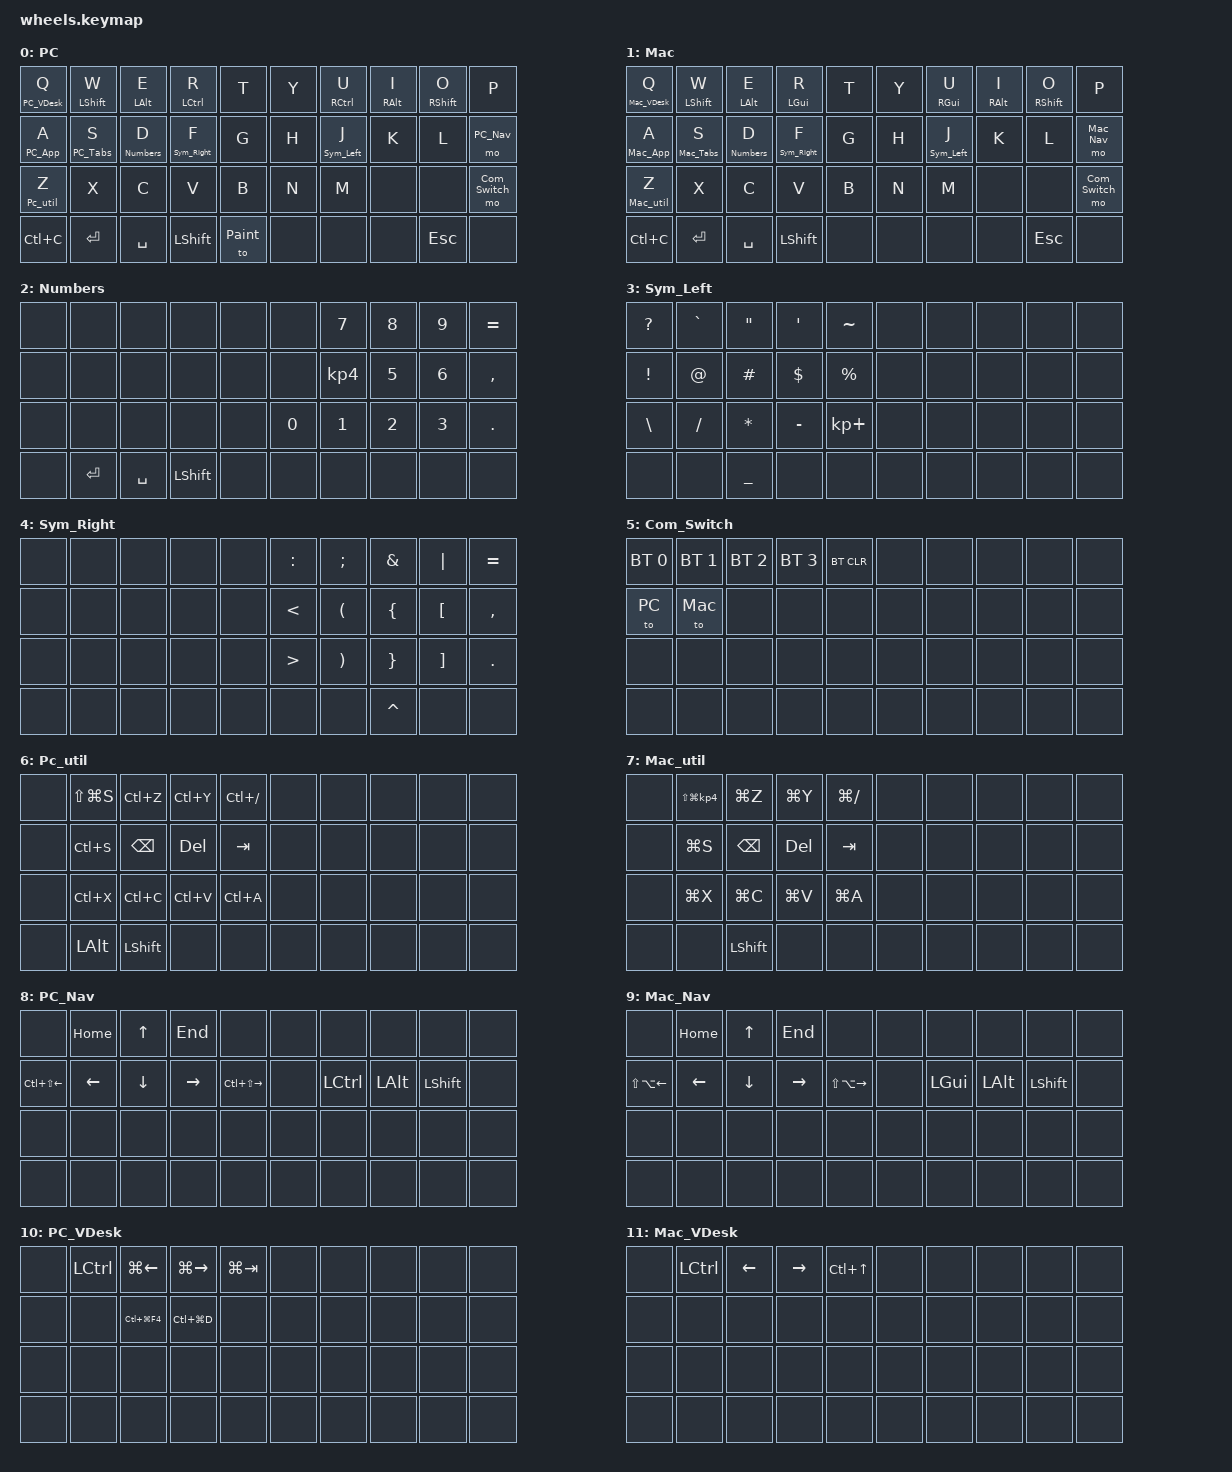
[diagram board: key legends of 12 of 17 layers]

/*
* Copyright (c) 2020 The ZMK Contributors 
* SPDX-License-Identifier: MIT 
*/ 

#include <behaviors.dtsi> 
#include <dt-bindings/zmk/keys.h> 
#include <dt-bindings/zmk/bt.h> 

#define PC 0 
#define Mac 1 
#define Numbers 2 
#define Sym_Left 3 
#define Sym_Right 4 
#define Com_Switch 5 
#define Pc_util 6 
#define Mac_util 7 
#define PC_Nav 8 
#define Mac_Nav 9 
#define PC_VDesk 10 
#define Mac_VDesk 11 
#define PC_App 12 
#define Mac_App 13 
#define PC_Tabs 14 
#define Mac_Tabs 15 
#define Paint 16 
    
/ {
    behaviors {
        hm: homerow_mods {
            compatible = "zmk,behavior-hold-tap";
            label = "HOMEROW_MODS";
            #binding-cells = <2>;
            tapping-term-ms = <300>;
            quick-tap-ms = <200>;
            flavor = "tap-preferred";
            bindings = <&kp>, <&kp>;
        };
    };
    keymap {
    compatible = "zmk,keymap";

    PC_layer {
            label = "PC";
            sensor-bindings = < 
              &inc_dec_kp   A   B // 1st: Targets left_horizonal_encoder
              &inc_dec_kp   PAGE_DOWN   PAGE_UP // 2nd: Targets left_vertical_encoder
              >;
            bindings = <
                          &lt PC_VDesk Q   &hm LSHIFT W     &hm LALT E       &hm LCTRL R      &kp T            &kp Y            &hm RCTRL U      &hm RALT I       &hm RSHIFT O     &kp P             
                          &lt PC_App A     &lt PC_Tabs S    &lt Numbers D    &lt Sym_Right F  &kp G            &kp H            &lt Sym_Left J   &kp K            &kp L            &mo PC_Nav        
                          &lt Pc_util Z    &kp X            &kp C            &kp V            &kp B            &kp N            &kp M            &none            &none            &mo Com_Switch    
                          &kp LC(C)        &kp ENTER        &kp SPACE        &kp LSHIFT       &to Paint        &none            &none            &none            &kp ESC          &none             
            >;
          };
            
Mac_layer {
            label = "Mac";
            sensor-bindings = < 
              &inc_dec_kp  0  0 // 1st: Targets left_horizonal_encoder
              &inc_dec_kp  0  0 // 2nd: Targets left_vertical_encoder
              >;
            bindings = <
                          &lt Mac_VDesk Q  &hm LSHIFT W     &hm LALT E       &hm LGUI R       &kp T            &kp Y            &hm RGUI U       &hm RALT I       &hm RSHIFT O     &kp P             
                          &lt Mac_App A    &lt Mac_Tabs S   &lt Numbers D    &lt Sym_Right F  &kp G            &kp H            &lt Sym_Left J   &kp K            &kp L            &mo Mac_Nav       
                          &lt Mac_util Z   &kp X            &kp C            &kp V            &kp B            &kp N            &kp M            &none            &none            &mo Com_Switch    
                          &kp LC(C)        &kp ENTER        &kp SPACE        &kp LSHIFT       &none            &none            &none            &none            &kp ESC          &none             
            >;
          };
            
Numbers_layer {
            label = "Numbers";
            sensor-bindings = < 
              &inc_dec_kp  0  0 // 1st: Targets left_horizonal_encoder
              &inc_dec_kp  0  0 // 2nd: Targets left_vertical_encoder
              >;
            bindings = <
                          &none            &none            &none            &none            &none            &none            &kp N7           &kp N8           &kp N9           &kp EQUAL         
                          &none            &none            &none            &none            &none            &none            &kp KP_N4        &kp N5           &kp N6           &kp COMMA         
                          &none            &none            &none            &none            &none            &kp N0           &kp N1           &kp N2           &kp N3           &kp DOT           
                          &none            &kp ENTER        &kp SPACE        &kp LSHIFT       &none            &none            &none            &none            &none            &none             
            >;
          };
            
Sym_Left_layer {
            label = "Sym_Left";
            sensor-bindings = < 
              &inc_dec_kp  0  0 // 1st: Targets left_horizonal_encoder
              &inc_dec_kp  0  0 // 2nd: Targets left_vertical_encoder
              >;
            bindings = <
                          &kp QMARK        &kp GRAVE        &kp DQT          &kp SINGLE_QUOTE &kp TILDE        &none            &none            &none            &none            &none             
                          &kp EXCL         &kp AT           &kp HASH         &kp DOLLAR       &kp PERCENT      &none            &none            &none            &none            &none             
                          &kp BACKSLASH    &kp SLASH        &kp ASTRK        &kp MINUS        &kp KP_PLUS      &none            &none            &none            &none            &none             
                          &none            &none            &kp UNDERSCORE   &none            &none            &none            &none            &none            &none            &none             
            >;
          };
            
Sym_Right_layer {
            label = "Sym_Right";
            sensor-bindings = < 
              &inc_dec_kp  0  0 // 1st: Targets left_horizonal_encoder
              &inc_dec_kp  0  0 // 2nd: Targets left_vertical_encoder
              >;
            bindings = <
                          &none            &none            &none            &none            &none            &kp COLON        &kp SEMICOLON    &kp AMPERSAND    &kp PIPE         &kp EQUAL         
                          &none            &none            &none            &none            &none            &kp LESS_THAN    &kp LPAR         &kp LBRC         &kp LBKT         &kp COMMA         
                          &none            &none            &none            &none            &none            &kp GREATER_THAN &kp RPAR         &kp RBRC         &kp  RBKT        &kp DOT           
                          &none            &none            &none            &none            &none            &none            &none            &kp CARET        &none            &none             
            >;
          };
            
Com_Switch_layer {
            label = "Com_Switch";
            sensor-bindings = < 
              &inc_dec_kp  0  0 // 1st: Targets left_horizonal_encoder
              &inc_dec_kp  0  0 // 2nd: Targets left_vertical_encoder
              >;
            bindings = <
                          &bt BT_SEL 0     &bt BT_SEL 1     &bt BT_SEL 2     &bt BT_SEL 3     &bt BT_CLR       &none            &none            &none            &none            &none             
                          &to PC           &to Mac          &none            &none            &none            &none            &none            &none            &none            &none             
                          &none            &none            &none            &none            &none            &none            &none            &none            &none            &none             
                          &none            &none            &none            &none            &none            &none            &none            &none            &none            &none             
            >;
          };
            
Pc_util_layer {
            label = "Pc_util";
            sensor-bindings = < 
              &inc_dec_kp  0  0 // 1st: Targets left_horizonal_encoder
              &inc_dec_kp  0  0 // 2nd: Targets left_vertical_encoder
              >;
            bindings = <
                          &none            &kp LS(LG(S))    &kp LC(Z)        &kp LC(Y)        &kp LC(SLASH)    &none            &none            &none            &none            &none             
                          &none            &kp LC(S)        &kp BACKSPACE    &kp DEL          &kp TAB          &none            &none            &none            &none            &none             
                          &none            &kp LC(X)        &kp LC(C)        &kp LC(V)        &kp LC(A)        &none            &none            &none            &none            &none             
                          &none            &kp LALT         &kp LSHIFT       &none            &none            &none            &none            &none            &none            &none             
            >;
          };
            
Mac_util_layer {
            label = "Mac_util";
            sensor-bindings = < 
              &inc_dec_kp  0  0 // 1st: Targets left_horizonal_encoder
              &inc_dec_kp  0  0 // 2nd: Targets left_vertical_encoder
              >;
            bindings = <
                          &none            &kp LS(LG(KP_N4)) &kp LG(Z)        &kp LG(Y)        &kp LG(SLASH)    &none            &none            &none            &none            &none             
                          &none            &kp LG(S)        &kp BACKSPACE    &kp DEL          &kp TAB          &none            &none            &none            &none            &none             
                          &none            &kp LG(X)        &kp LG(C)        &kp LG(V)        &kp LG(A)        &none            &none            &none            &none            &none             
                          &none            &none            &kp LSHIFT       &none            &none            &none            &none            &none            &none            &none             
            >;
          };
            
PC_Nav_layer {
            label = "PC_Nav";
            sensor-bindings = < 
              &inc_dec_kp  0  0 // 1st: Targets left_horizonal_encoder
              &inc_dec_kp  0  0 // 2nd: Targets left_vertical_encoder
              >;
            bindings = <
                          &none            &kp HOME         &kp UP           &kp END          &none            &none            &none            &none            &none            &none             
                          &kp LC(LS(LEFT)) &kp LEFT         &kp DOWN         &kp RIGHT        &kp LC(LS(RIGHT)) &none            &kp LCTRL        &kp LALT         &kp LSHIFT       &none             
                          &none            &none            &none            &none            &none            &none            &none            &none            &none            &none             
                          &none            &none            &none            &none            &none            &none            &none            &none            &none            &none             
            >;
          };
            
Mac_Nav_layer {
            label = "Mac_Nav";
            sensor-bindings = < 
              &inc_dec_kp  0  0 // 1st: Targets left_horizonal_encoder
              &inc_dec_kp  0  0 // 2nd: Targets left_vertical_encoder
              >;
            bindings = <
                          &none            &kp HOME         &kp UP           &kp END          &none            &none            &none            &none            &none            &none             
                          &kp LS(LA(LEFT)) &kp LEFT         &kp DOWN         &kp RIGHT        &kp LS(LA(RIGHT)) &none            &kp LGUI         &kp LALT         &kp LSHIFT       &none             
                          &none            &none            &none            &none            &none            &none            &none            &none            &none            &none             
                          &none            &none            &none            &none            &none            &none            &none            &none            &none            &none             
            >;
          };
            
PC_VDesk_layer {
            label = "PC_VDesk";
            sensor-bindings = < 
              &inc_dec_kp  0  0 // 1st: Targets left_horizonal_encoder
              &inc_dec_kp  0  0 // 2nd: Targets left_vertical_encoder
              >;
            bindings = <
                          &none            &kp LCTRL        &kp LG(LEFT)     &kp LG(RIGHT)    &kp LG(TAB)      &none            &none            &none            &none            &none             
                          &none            &none            &kp LC(LG(F4))   &kp LC(LG(D))    &none            &none            &none            &none            &none            &none             
                          &none            &none            &none            &none            &none            &none            &none            &none            &none            &none             
                          &none            &none            &none            &none            &none            &none            &none            &none            &none            &none             
            >;
          };
            
Mac_VDesk_layer {
            label = "Mac_VDesk";
            sensor-bindings = < 
              &inc_dec_kp  0  0 // 1st: Targets left_horizonal_encoder
              &inc_dec_kp  0  0 // 2nd: Targets left_vertical_encoder
              >;
            bindings = <
                          &none            &kp LCTRL        &kp LEFT         &kp RIGHT        &kp LC(UP)       &none            &none            &none            &none            &none             
                          &none            &none            &none            &none            &none            &none            &none            &none            &none            &none             
                          &none            &none            &none            &none            &none            &none            &none            &none            &none            &none             
                          &none            &none            &none            &none            &none            &none            &none            &none            &none            &none             
            >;
          };
            
PC_App_layer {
            label = "PC_App";
            sensor-bindings = < 
              &inc_dec_kp  0  0 // 1st: Targets left_horizonal_encoder
              &inc_dec_kp  0  0 // 2nd: Targets left_vertical_encoder
              >;
            bindings = <
                          &none            &none            &none            &none            &none            &none            &none            &none            &none            &none             
                          &none            &kp LALT         &kp LS(TAB)      &kp TAB          &none            &none            &none            &none            &none            &none             
                          &none            &none            &kp LA(F4)       &none            &none            &none            &none            &none            &none            &none             
                          &none            &none            &none            &none            &none            &none            &none            &none            &none            &none             
            >;
          };
            
Mac_App_layer {
            label = "Mac_App";
            sensor-bindings = < 
              &inc_dec_kp  0  0 // 1st: Targets left_horizonal_encoder
              &inc_dec_kp  0  0 // 2nd: Targets left_vertical_encoder
              >;
            bindings = <
                          &none            &none            &kp TILDE        &kp GRAVE        &kp W            &none            &none            &none            &none            &none             
                          &none            &kp LGUI         &kp LS(TAB)      &kp TAB          &none            &none            &none            &none            &none            &none             
                          &none            &none            &kp Q            &kp SPACE        &none            &none            &none            &none            &none            &none             
                          &none            &none            &none            &none            &none            &none            &none            &none            &none            &none             
            >;
          };
            
PC_Tabs_layer {
            label = "PC_Tabs";
            sensor-bindings = < 
              &inc_dec_kp  0  0 // 1st: Targets left_horizonal_encoder
              &inc_dec_kp  0  0 // 2nd: Targets left_vertical_encoder
              >;
            bindings = <
                          &none            &none            &kp LC(LS(PAGE_UP)) &kp LC(LS(PAGE_DOWN)) &none            &none            &none            &none            &none            &none             
                          &none            &none            &kp LC(PAGE_UP)  &kp LC(PAGE_DOWN) &kp LS(LC(T))    &none            &none            &none            &none            &none             
                          &none            &none            &kp LC(W)        &kp LC(T)        &none            &none            &none            &none            &none            &none             
                          &none            &none            &none            &none            &none            &none            &none            &none            &none            &none             
            >;
          };
            
Mac_Tabs_layer {
            label = "Mac_Tabs";
            sensor-bindings = < 
              &inc_dec_kp  0  0 // 1st: Targets left_horizonal_encoder
              &inc_dec_kp  0  0 // 2nd: Targets left_vertical_encoder
              >;
            bindings = <
                          &none            &none            &kp LS(LC(PAGE_UP)) &kp LS(LC(PAGE_DOWN)) &none            &none            &none            &none            &none            &none             
                          &none            &none            &kp LA(LG(LEFT)) &kp LA(LG(RIGHT)) &kp LS(LG(T))    &none            &none            &none            &none            &none             
                          &none            &none            &kp LG(W)        &kp LG(T)        &none            &none            &none            &none            &none            &none             
                          &none            &none            &none            &none            &none            &none            &none            &none            &none            &none             
            >;
          };
            
Paint_layer {
            label = "Paint";
            sensor-bindings = < 
              &inc_dec_kp    RBKT   LBKT // 1st: Targets left_horizonal_encoder
              &inc_dec_kp   LC(MINUS)   LC(KP_PLUS) // 2nd: Targets left_vertical_encoder
              >;
            bindings = <
                          &kp LC(C)        &kp LC(V)        &kp LS(LC(B))    &kp T            &kp LC(T)        &none            &none            &none            &none            &none             
                          &kp LS(LC(L))    &kp LC(E)        &kp BACKSPACE    &kp P            &kp E            &none            &none            &none            &none            &none             
                          &kp N2           &kp LC(Z)        &kp LS(LC(Z))    &kp B            &kp F            &none            &none            &none            &none            &none             
                          &kp LC(S)        &kp ENTER        &kp LALT         &kp LSHIFT       &to PC           &none            &none            &none            &none            &none             
            >;
          };
            
    };
};
    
